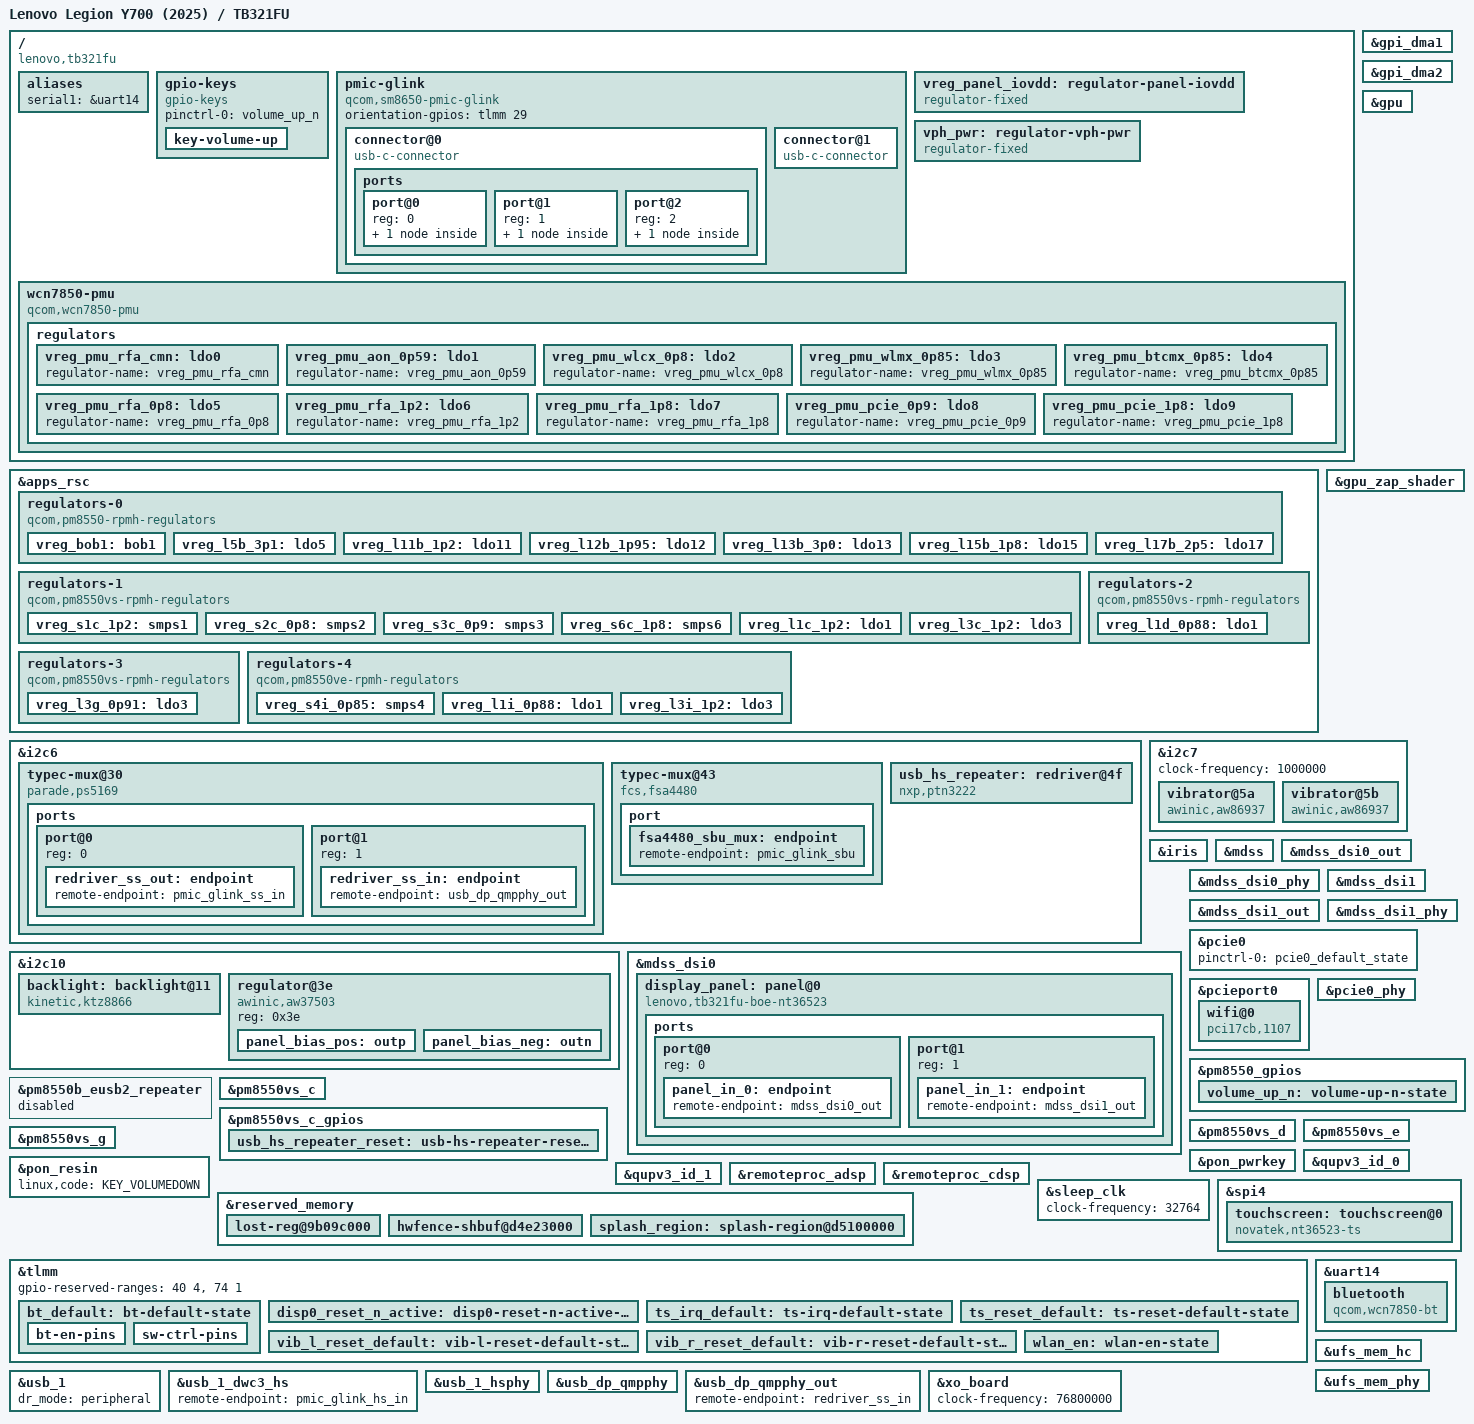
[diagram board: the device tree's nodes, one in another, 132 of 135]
// SPDX-License-Identifier: BSD-3-Clause
/*
 * Copyright (c) 2023, Linaro Limited
 */

/dts-v1/;

#include <dt-bindings/phy/phy.h>
#include <dt-bindings/regulator/qcom,rpmh-regulator.h>
#include "sm8650.dtsi"
#include "pm8550.dtsi"
#include "pm8550b.dtsi"
#define PMK8550VE_SID 8
#include "pm8550ve.dtsi"
#include "pm8550vs.dtsi"
#include "pmk8550.dtsi"

/ {
	model = "Lenovo Legion Y700 (2025) / TB321FU";
	compatible = "lenovo,tb321fu", "qcom,sm8650";
	chassis-type = "tablet";

	aliases {
		serial1 = &uart14;
	};

	gpio-keys {
		compatible = "gpio-keys";

		pinctrl-0 = <&volume_up_n>;
		pinctrl-names = "default";

		key-volume-up {
			label = "Volume Up";
			linux,code = <KEY_VOLUMEUP>;
			gpios = <&pm8550_gpios 6 GPIO_ACTIVE_LOW>;
			debounce-interval = <15>;
			linux,can-disable;
			wakeup-source;
		};
	};

	pmic-glink {
		compatible = "qcom,sm8650-pmic-glink",
			     "qcom,sm8550-pmic-glink",
			     "qcom,pmic-glink";
		#address-cells = <1>;
		#size-cells = <0>;
		orientation-gpios = <&tlmm 29 GPIO_ACTIVE_HIGH>;

		connector@0 {
			compatible = "usb-c-connector";
			reg = <0>;

			power-role = "dual";
			data-role = "dual";

			ports {
				#address-cells = <1>;
				#size-cells = <0>;

				port@0 {
					reg = <0>;

					pmic_glink_hs_in: endpoint {
						remote-endpoint = <&usb_1_dwc3_hs>;
					};
				};

				port@1 {
					reg = <1>;

					pmic_glink_ss_in: endpoint {
						remote-endpoint = <&redriver_ss_out>;
					};
				};

				port@2 {
					reg = <2>;

					pmic_glink_sbu: endpoint {
						remote-endpoint = <&fsa4480_sbu_mux>;
					};
				};
			};
		};

		connector@1 {
			compatible = "usb-c-connector";
			reg = <1>;

			power-role = "dual";
			data-role = "dual";
		};
	};

	vreg_panel_iovdd: regulator-panel-iovdd {
		compatible = "regulator-fixed";

		regulator-name = "panel_iovdd";
		regulator-min-microvolt = <1950000>;
		regulator-max-microvolt = <1950000>;

		gpio = <&pm8550ve_gpios 8 GPIO_ACTIVE_HIGH>;
		enable-active-high;
		vin-supply = <&vreg_l12b_1p95>;

		regulator-boot-on;
	};

	vph_pwr: regulator-vph-pwr {
		compatible = "regulator-fixed";

		regulator-name = "vph_pwr";
		regulator-min-microvolt = <3700000>;
		regulator-max-microvolt = <3700000>;

		regulator-always-on;
		regulator-boot-on;
	};

	wcn7850-pmu {
		compatible = "qcom,wcn7850-pmu";

		pinctrl-0 = <&wlan_en>, <&bt_default>;
		pinctrl-names = "default";

		wlan-enable-gpios = <&tlmm 16 GPIO_ACTIVE_HIGH>;
		bt-enable-gpios = <&tlmm 17 GPIO_ACTIVE_HIGH>;

		vdd-supply = <&vreg_s4i_0p85>;
		vddio-supply = <&vreg_l15b_1p8>;
		vddio1p2-supply = <&vreg_l3c_1p2>;
		vddaon-supply = <&vreg_s2c_0p8>;
		vdddig-supply = <&vreg_s3c_0p9>;
		vddrfa1p2-supply = <&vreg_s1c_1p2>;
		vddrfa1p8-supply = <&vreg_s6c_1p8>;

		clocks = <&rpmhcc RPMH_RF_CLK1>;

		regulators {
			vreg_pmu_rfa_cmn: ldo0 {
				regulator-name = "vreg_pmu_rfa_cmn";
			};

			vreg_pmu_aon_0p59: ldo1 {
				regulator-name = "vreg_pmu_aon_0p59";
			};

			vreg_pmu_wlcx_0p8: ldo2 {
				regulator-name = "vreg_pmu_wlcx_0p8";
			};

			vreg_pmu_wlmx_0p85: ldo3 {
				regulator-name = "vreg_pmu_wlmx_0p85";
			};

			vreg_pmu_btcmx_0p85: ldo4 {
				regulator-name = "vreg_pmu_btcmx_0p85";
			};

			vreg_pmu_rfa_0p8: ldo5 {
				regulator-name = "vreg_pmu_rfa_0p8";
			};

			vreg_pmu_rfa_1p2: ldo6 {
				regulator-name = "vreg_pmu_rfa_1p2";
			};

			vreg_pmu_rfa_1p8: ldo7 {
				regulator-name = "vreg_pmu_rfa_1p8";
			};

			vreg_pmu_pcie_0p9: ldo8 {
				regulator-name = "vreg_pmu_pcie_0p9";
			};

			vreg_pmu_pcie_1p8: ldo9 {
				regulator-name = "vreg_pmu_pcie_1p8";
			};
		};
	};
};

&apps_rsc {
	regulators-0 {
		compatible = "qcom,pm8550-rpmh-regulators";

		vdd-bob1-supply = <&vph_pwr>;
		vdd-l2-l13-l14-supply = <&vreg_bob1>;
		vdd-l3-supply = <&vreg_s1c_1p2>;
		vdd-l5-l16-supply = <&vreg_bob1>;
		vdd-l6-l7-supply = <&vreg_bob1>;
		vdd-l8-l9-supply = <&vreg_bob1>;
		vdd-l11-supply = <&vreg_s1c_1p2>;
		vdd-l12-supply = <&vreg_s6c_1p8>;
		vdd-l15-supply = <&vreg_s6c_1p8>;

		qcom,pmic-id = "b";

		vreg_bob1: bob1 {
			regulator-name = "vreg_bob1";
			regulator-min-microvolt = <3296000>;
			regulator-max-microvolt = <3960000>;
			regulator-initial-mode = <RPMH_REGULATOR_MODE_HPM>;
		};

		vreg_l5b_3p1: ldo5 {
			regulator-name = "vreg_l5b_3p1";
			regulator-min-microvolt = <3104000>;
			regulator-max-microvolt = <3104000>;
			regulator-initial-mode = <RPMH_REGULATOR_MODE_HPM>;
			regulator-allow-set-load;
			regulator-allowed-modes = <RPMH_REGULATOR_MODE_LPM
						   RPMH_REGULATOR_MODE_HPM>;
		};

		vreg_l11b_1p2: ldo11 {
			regulator-name = "vreg_l11b_1p2";
			regulator-min-microvolt = <1200000>;
			regulator-max-microvolt = <1200000>;
			regulator-initial-mode = <RPMH_REGULATOR_MODE_HPM>;
			regulator-allow-set-load;
			regulator-allowed-modes = <RPMH_REGULATOR_MODE_LPM
						   RPMH_REGULATOR_MODE_HPM>;
		};

		vreg_l12b_1p95: ldo12 {
			regulator-name = "vreg_l12b_1p95";
			regulator-min-microvolt = <1800000>;
			regulator-max-microvolt = <1800000>;
			regulator-initial-mode = <RPMH_REGULATOR_MODE_HPM>;
			regulator-allow-set-load;
			regulator-allowed-modes = <RPMH_REGULATOR_MODE_LPM
						   RPMH_REGULATOR_MODE_HPM>;
		};

		vreg_l13b_3p0: ldo13 {
			regulator-name = "vreg_l13b_3p0";
			regulator-min-microvolt = <3000000>;
			regulator-max-microvolt = <3000000>;
			regulator-initial-mode = <RPMH_REGULATOR_MODE_HPM>;
			regulator-allow-set-load;
			regulator-allowed-modes = <RPMH_REGULATOR_MODE_LPM
						   RPMH_REGULATOR_MODE_HPM>;
		};

		vreg_l15b_1p8: ldo15 {
			regulator-name = "vreg_l15b_1p8";
			regulator-min-microvolt = <1800000>;
			regulator-max-microvolt = <1800000>;
			regulator-initial-mode = <RPMH_REGULATOR_MODE_HPM>;
			regulator-allow-set-load;
			regulator-allowed-modes = <RPMH_REGULATOR_MODE_LPM
						   RPMH_REGULATOR_MODE_HPM>;
		};

		vreg_l17b_2p5: ldo17 {
			regulator-name = "vreg_l17b_2p5";
			regulator-min-microvolt = <2504000>;
			regulator-max-microvolt = <2504000>;
			regulator-initial-mode = <RPMH_REGULATOR_MODE_HPM>;
			regulator-allow-set-load;
			regulator-allowed-modes = <RPMH_REGULATOR_MODE_LPM
						   RPMH_REGULATOR_MODE_HPM>;
		};
	};

	regulators-1 {
		compatible = "qcom,pm8550vs-rpmh-regulators";

		vdd-l1-supply = <&vreg_s1c_1p2>;
		vdd-l2-supply = <&vreg_s1c_1p2>;
		vdd-l3-supply = <&vreg_s1c_1p2>;
		vdd-s1-supply = <&vph_pwr>;
		vdd-s2-supply = <&vph_pwr>;
		vdd-s3-supply = <&vph_pwr>;
		vdd-s4-supply = <&vph_pwr>;
		vdd-s5-supply = <&vph_pwr>;
		vdd-s6-supply = <&vph_pwr>;

		qcom,pmic-id = "c";

		vreg_s1c_1p2: smps1 {
			regulator-name = "vreg_s1c_1p2";
			regulator-min-microvolt = <1256000>;
			regulator-max-microvolt = <1348000>;
			regulator-initial-mode = <RPMH_REGULATOR_MODE_HPM>;
		};

		vreg_s2c_0p8: smps2 {
			regulator-name = "vreg_s2c_0p8";
			regulator-min-microvolt = <852000>;
			regulator-max-microvolt = <1036000>;
			regulator-initial-mode = <RPMH_REGULATOR_MODE_HPM>;
		};

		vreg_s3c_0p9: smps3 {
			regulator-name = "vreg_s3c_0p9";
			regulator-min-microvolt = <976000>;
			regulator-max-microvolt = <1064000>;
			regulator-initial-mode = <RPMH_REGULATOR_MODE_HPM>;
		};

		vreg_s6c_1p8: smps6 {
			regulator-name = "vreg_s6c_1p8";
			regulator-min-microvolt = <1856000>;
			regulator-max-microvolt = <2000000>;
			regulator-initial-mode = <RPMH_REGULATOR_MODE_HPM>;
		};

		vreg_l1c_1p2: ldo1 {
			regulator-name = "vreg_l1c_1p2";
			regulator-min-microvolt = <1200000>;
			regulator-max-microvolt = <1200000>;
			regulator-initial-mode = <RPMH_REGULATOR_MODE_HPM>;
			regulator-allow-set-load;
			regulator-allowed-modes = <RPMH_REGULATOR_MODE_LPM
						   RPMH_REGULATOR_MODE_HPM>;
		};

		vreg_l3c_1p2: ldo3 {
			regulator-name = "vreg_l3c_1p2";
			regulator-min-microvolt = <1200000>;
			regulator-max-microvolt = <1200000>;
			regulator-initial-mode = <RPMH_REGULATOR_MODE_HPM>;
			regulator-allow-set-load;
			regulator-allowed-modes = <RPMH_REGULATOR_MODE_LPM
						   RPMH_REGULATOR_MODE_HPM>;
		};
	};

	regulators-2 {
		compatible = "qcom,pm8550vs-rpmh-regulators";

		vdd-l1-supply = <&vreg_s3c_0p9>;

		qcom,pmic-id = "d";

		vreg_l1d_0p88: ldo1 {
			regulator-name = "vreg_l1d_0p88";
			regulator-min-microvolt = <912000>;
			regulator-max-microvolt = <920000>;
			regulator-initial-mode = <RPMH_REGULATOR_MODE_HPM>;
			regulator-allow-set-load;
			regulator-allowed-modes = <RPMH_REGULATOR_MODE_LPM
						   RPMH_REGULATOR_MODE_HPM>;
		};
	};

	regulators-3 {
		compatible = "qcom,pm8550vs-rpmh-regulators";

		vdd-l3-supply = <&vreg_s3c_0p9>;

		qcom,pmic-id = "g";

		vreg_l3g_0p91: ldo3 {
			regulator-name = "vreg_l3g_0p91";
			regulator-min-microvolt = <880000>;
			regulator-max-microvolt = <912000>;
			regulator-initial-mode = <RPMH_REGULATOR_MODE_HPM>;
			regulator-allow-set-load;
			regulator-allowed-modes = <RPMH_REGULATOR_MODE_LPM
						   RPMH_REGULATOR_MODE_HPM>;
		};
	};

	regulators-4 {
		compatible = "qcom,pm8550ve-rpmh-regulators";

		vdd-l1-supply = <&vreg_s3c_0p9>;
		vdd-l3-supply = <&vreg_s1c_1p2>;
		vdd-s4-supply = <&vph_pwr>;

		qcom,pmic-id = "i";

		vreg_s4i_0p85: smps4 {
			regulator-name = "vreg_s4i_0p85";
			regulator-min-microvolt = <852000>;
			regulator-max-microvolt = <1004000>;
			regulator-initial-mode = <RPMH_REGULATOR_MODE_HPM>;
		};

		vreg_l1i_0p88: ldo1 {
			regulator-name = "vreg_l1i_0p88";
			regulator-min-microvolt = <880000>;
			regulator-max-microvolt = <912000>;
			regulator-initial-mode = <RPMH_REGULATOR_MODE_HPM>;
			regulator-allow-set-load;
			regulator-allowed-modes = <RPMH_REGULATOR_MODE_LPM
						   RPMH_REGULATOR_MODE_HPM>;
		};

		vreg_l3i_1p2: ldo3 {
			regulator-name = "vreg_l3i_1p2";
			regulator-min-microvolt = <1200000>;
			regulator-max-microvolt = <1200000>;
			regulator-initial-mode = <RPMH_REGULATOR_MODE_HPM>;
			regulator-allow-set-load;
			regulator-allowed-modes = <RPMH_REGULATOR_MODE_LPM
						   RPMH_REGULATOR_MODE_HPM>;
		};
	};
};

&gpi_dma1 {
	status = "okay";
};

&gpi_dma2 {
	status = "okay";
};

&gpu {
	status = "okay";
};

&gpu_zap_shader {
	firmware-name = "qcom/sm8650/lenovo/tb321fu/gen70900_zap.mbn";
};

&i2c6 {
	status = "okay";

	typec-mux@30 {
		compatible = "parade,ps5169";
		reg = <0x30>;

		orientation-switch;
		retimer-switch;

		ports {
			#address-cells = <1>;
			#size-cells = <0>;

			port@0 {
				reg = <0>;

				redriver_ss_out: endpoint {
					remote-endpoint = <&pmic_glink_ss_in>;
				};
			};

			port@1 {
				reg = <1>;

				redriver_ss_in: endpoint {
					remote-endpoint = <&usb_dp_qmpphy_out>;
				};
			};
		};
	};

	typec-mux@43 {
		compatible = "fcs,fsa4480";
		reg = <0x43>;

		mode-switch;
		orientation-switch;

		port {
			fsa4480_sbu_mux: endpoint {
				remote-endpoint = <&pmic_glink_sbu>;
			};
		};
	};

	usb_hs_repeater: redriver@4f {
		compatible = "nxp,ptn3222";
		reg = <0x4f>;
		#phy-cells = <0>;

		vdd1v8-supply = <&vreg_l15b_1p8>;
		vdd3v3-supply = <&vreg_l5b_3p1>;

		reset-gpios = <&pm8550vs_c_gpios 4 GPIO_ACTIVE_LOW>;

		pinctrl-0 = <&usb_hs_repeater_reset>;
		pinctrl-names = "default";
	};
};

&i2c7 {
	clock-frequency = <1000000>;

	status = "okay";

	vibrator@5a {
		compatible = "awinic,aw86937", "awinic,aw86927";
		reg = <0x5a>;

		interrupts-extended = <&tlmm 92 IRQ_TYPE_EDGE_FALLING>;
		reset-gpios = <&tlmm 127 GPIO_ACTIVE_LOW>;

		pinctrl-0 = <&vib_r_reset_default>;
		pinctrl-names = "default";
	};

	vibrator@5b {
		compatible = "awinic,aw86937", "awinic,aw86927";
		reg = <0x5b>;

		interrupts-extended = <&tlmm 88 IRQ_TYPE_EDGE_FALLING>;
		reset-gpios = <&tlmm 119 GPIO_ACTIVE_LOW>;

		pinctrl-0 = <&vib_l_reset_default>;
		pinctrl-names = "default";
	};
};

&i2c10 {
	status = "okay";

	backlight: backlight@11 {
		compatible = "kinetic,ktz8866";
		reg = <0x11>;

		vddpos-supply = <&panel_bias_pos>;
		vddneg-supply = <&panel_bias_neg>;
		enable-gpios = <&tlmm 87 GPIO_ACTIVE_HIGH>;

		current-num-sinks = <4>;
		kinetic,inductor-nanohenry = <4700>;
		kinetic,ovp-microvolt = <34000000>;
		led-max-microamp = <15600>;
	};

	regulator@3e {
		compatible = "awinic,aw37503";
		reg = <0x3e>;

		panel_bias_pos: outp {
			regulator-name = "panel_bias_pos";
			regulator-min-microvolt = <5800000>;
			regulator-max-microvolt = <5800000>;
			enable-gpios = <&tlmm 72 GPIO_ACTIVE_HIGH>;
		};

		panel_bias_neg: outn {
			regulator-name = "panel_bias_neg";
			regulator-min-microvolt = <5800000>;
			regulator-max-microvolt = <5800000>;
			enable-gpios = <&tlmm 73 GPIO_ACTIVE_HIGH>;
		};
	};
};

&iris {
	firmware-name = "qcom/sm8650/lenovo/tb321fu/vpu33_p4.mbn";

	status = "okay";
};

&mdss {
	status = "okay";
};

&mdss_dsi0 {
	vdda-supply = <&vreg_l3i_1p2>;
	qcom,dual-dsi-mode;
	qcom,sync-dual-dsi;
	qcom,master-dsi;

	status = "okay";

	display_panel: panel@0 {
		compatible = "lenovo,tb321fu-boe-nt36523", "novatek,nt36523";
		reg = <0>;

		vddio-supply = <&vreg_panel_iovdd>;
		vci-supply = <&vreg_l13b_3p0>;
		vdd-supply = <&vreg_l11b_1p2>;
		reset-gpios = <&tlmm 133 GPIO_ACTIVE_LOW>;
		backlight = <&backlight>;

		pinctrl-0 = <&disp0_reset_n_active>;
		pinctrl-names = "default";

		ports {
			#address-cells = <1>;
			#size-cells = <0>;

			port@0 {
				reg = <0>;

				panel_in_0: endpoint {
					remote-endpoint = <&mdss_dsi0_out>;
				};
			};

			port@1 {
				reg = <1>;

				panel_in_1: endpoint {
					remote-endpoint = <&mdss_dsi1_out>;
				};
			};
		};
	};
};

&mdss_dsi0_out {
	data-lanes = <0 1 2>;
	remote-endpoint = <&panel_in_0>;
};

&mdss_dsi0_phy {
	vdds-supply = <&vreg_l1i_0p88>;
	phy-type = <PHY_TYPE_CPHY>;

	status = "okay";
};

&mdss_dsi1 {
	vdda-supply = <&vreg_l3i_1p2>;
	qcom,dual-dsi-mode;
	qcom,sync-dual-dsi;
	assigned-clock-parents = <&mdss_dsi0_phy DSI_BYTE_PLL_CLK>,
				 <&mdss_dsi0_phy DSI_PIXEL_PLL_CLK>;

	status = "okay";
};

&mdss_dsi1_out {
	data-lanes = <0 1 2>;
	remote-endpoint = <&panel_in_1>;
};

&mdss_dsi1_phy {
	vdds-supply = <&vreg_l1i_0p88>;
	phy-type = <PHY_TYPE_CPHY>;

	status = "okay";
};

&pcie0 {
	pinctrl-0 = <&pcie0_default_state>;
	pinctrl-names = "default";

	status = "okay";
};

&pcieport0 {
	reset-gpios = <&tlmm 94 GPIO_ACTIVE_LOW>;
	wake-gpios = <&tlmm 96 GPIO_ACTIVE_LOW>;

	wifi@0 {
		compatible = "pci17cb,1107";
		reg = <0x10000 0x0 0x0 0x0 0x0>;

		vddrfacmn-supply = <&vreg_pmu_rfa_cmn>;
		vddaon-supply = <&vreg_pmu_aon_0p59>;
		vddwlcx-supply = <&vreg_pmu_wlcx_0p8>;
		vddwlmx-supply = <&vreg_pmu_wlmx_0p85>;
		vddrfa0p8-supply = <&vreg_pmu_rfa_0p8>;
		vddrfa1p2-supply = <&vreg_pmu_rfa_1p2>;
		vddrfa1p8-supply = <&vreg_pmu_rfa_1p8>;
		vddpcie0p9-supply = <&vreg_pmu_pcie_0p9>;
		vddpcie1p8-supply = <&vreg_pmu_pcie_1p8>;
	};
};

&pcie0_phy {
	vdda-phy-supply = <&vreg_l1i_0p88>;
	vdda-pll-supply = <&vreg_l3i_1p2>;

	status = "okay";
};

&pm8550_gpios {
	volume_up_n: volume-up-n-state {
		pins = "gpio6";
		function = "normal";
		bias-pull-up;
		input-enable;
		power-source = <1>;
	};
};

&pm8550b_eusb2_repeater {
	status = "disabled";
};

&pm8550vs_c {
	status = "okay";
};

&pm8550vs_c_gpios {
	usb_hs_repeater_reset: usb-hs-repeater-reset-state {
		pins = "gpio4";
		function = "normal";
		power-source = <1>;
		output-enable;
		bias-disable;
	};
};

&pm8550vs_d {
	status = "okay";
};

&pm8550vs_e {
	status = "okay";
};

&pm8550vs_g {
	status = "okay";
};

&pon_pwrkey {
	status = "okay";
};

&pon_resin {
	linux,code = <KEY_VOLUMEDOWN>;

	status = "okay";
};

&qupv3_id_0 {
	status = "okay";
};

&qupv3_id_1 {
	status = "okay";
};

&remoteproc_adsp {
	firmware-name = "qcom/sm8650/lenovo/tb321fu/adsp.mdt",
			"qcom/sm8650/lenovo/tb321fu/adsp_dtb.mdt";

	status = "okay";
};

&remoteproc_cdsp {
	firmware-name = "qcom/sm8650/lenovo/tb321fu/cdsp.mdt",
			"qcom/sm8650/lenovo/tb321fu/cdsp_dtb.mdt";

	status = "okay";
};

&reserved_memory {
	lost-reg@9b09c000 {
		reg = <0 0x9b09c000 0 0x4000>;
		no-map;
	};

	hwfence-shbuf@d4e23000 {
		reg = <0 0xd4e23000 0 0x2dd000>;
		no-map;
	};

	splash_region: splash-region@d5100000 {
		reg = <0 0xd5100000 0 0x2b00000>;
		no-map;
	};
};

&sleep_clk {
	clock-frequency = <32764>;
};

&spi4 {
	status = "okay";

	touchscreen: touchscreen@0 {
		compatible = "novatek,nt36523-ts";
		reg = <0>;

		interrupts-extended = <&tlmm 162 IRQ_TYPE_EDGE_RISING>;
		reset-gpios = <&tlmm 161 GPIO_ACTIVE_LOW>;

		pinctrl-0 = <&ts_irq_default>, <&ts_reset_default>;
		pinctrl-names = "default";

		spi-max-frequency = <9600000>;

		firmware-name = "qcom/sm8650/lenovo/tb321fu/novatek_ts_boe_fw.bin";

		panel = <&display_panel>;

		touchscreen-size-x = <16000>;
		touchscreen-size-y = <25600>;
		touchscreen-x-mm = <118>;
		touchscreen-y-mm = <190>;
		touchscreen-inverted-x;
		touchscreen-swapped-x-y;
	};
};

&tlmm {
	gpio-reserved-ranges = <40 4>, <74 1>;

	bt_default: bt-default-state {
		bt-en-pins {
			pins = "gpio17";
			function = "gpio";
			drive-strength = <16>;
			bias-disable;
		};

		sw-ctrl-pins {
			pins = "gpio18";
			function = "gpio";
			bias-pull-down;
		};
	};

	disp0_reset_n_active: disp0-reset-n-active-state {
		pins = "gpio133";
		function = "gpio";
		drive-strength = <8>;
		bias-disable;
	};

	ts_irq_default: ts-irq-default-state {
		pins = "gpio162";
		function = "gpio";
		drive-strength = <2>;
		bias-disable;
	};

	ts_reset_default: ts-reset-default-state {
		pins = "gpio161";
		function = "gpio";
		drive-strength = <2>;
		bias-pull-up;
	};

	vib_l_reset_default: vib-l-reset-default-state {
		pins = "gpio119";
		function = "gpio";
		bias-pull-up;
	};

	vib_r_reset_default: vib-r-reset-default-state {
		pins = "gpio127";
		function = "gpio";
		bias-pull-up;
	};

	wlan_en: wlan-en-state {
		pins = "gpio16";
		function = "gpio";
		drive-strength = <8>;
		bias-pull-down;
	};
};

&uart14 {
	status = "okay";

	bluetooth {
		compatible = "qcom,wcn7850-bt";

		vddrfacmn-supply = <&vreg_pmu_rfa_cmn>;
		vddaon-supply = <&vreg_pmu_aon_0p59>;
		vddwlcx-supply = <&vreg_pmu_wlcx_0p8>;
		vddwlmx-supply = <&vreg_pmu_wlmx_0p85>;
		vddrfa0p8-supply = <&vreg_pmu_rfa_0p8>;
		vddrfa1p2-supply = <&vreg_pmu_rfa_1p2>;
		vddrfa1p8-supply = <&vreg_pmu_rfa_1p8>;

		firmware-name = "hmtnv20_Kirby_row.bin";

		max-speed = <3200000>;
	};
};

&ufs_mem_hc {
	reset-gpios = <&tlmm 210 GPIO_ACTIVE_LOW>;

	vcc-supply = <&vreg_l17b_2p5>;
	vcc-max-microamp = <1300000>;
	vccq-supply = <&vreg_l1c_1p2>;
	vccq-max-microamp = <1200000>;

	status = "okay";
};

&ufs_mem_phy {
	vdda-phy-supply = <&vreg_l1d_0p88>;
	vdda-pll-supply = <&vreg_l3i_1p2>;

	status = "okay";
};

&usb_1 {
	dr_mode = "peripheral";

	status = "okay";
};

&usb_1_dwc3_hs {
	remote-endpoint = <&pmic_glink_hs_in>;
};

&usb_1_hsphy {
	vdd-supply = <&vreg_l1i_0p88>;
	vdda12-supply = <&vreg_l3i_1p2>;

	phys = <&usb_hs_repeater>;

	status = "okay";
};

&usb_dp_qmpphy {
	vdda-phy-supply = <&vreg_l3g_0p91>;
	vdda-pll-supply = <&vreg_l3i_1p2>;

	status = "okay";
};

&usb_dp_qmpphy_out {
	remote-endpoint = <&redriver_ss_in>;
};

&xo_board {
	clock-frequency = <76800000>;
};
